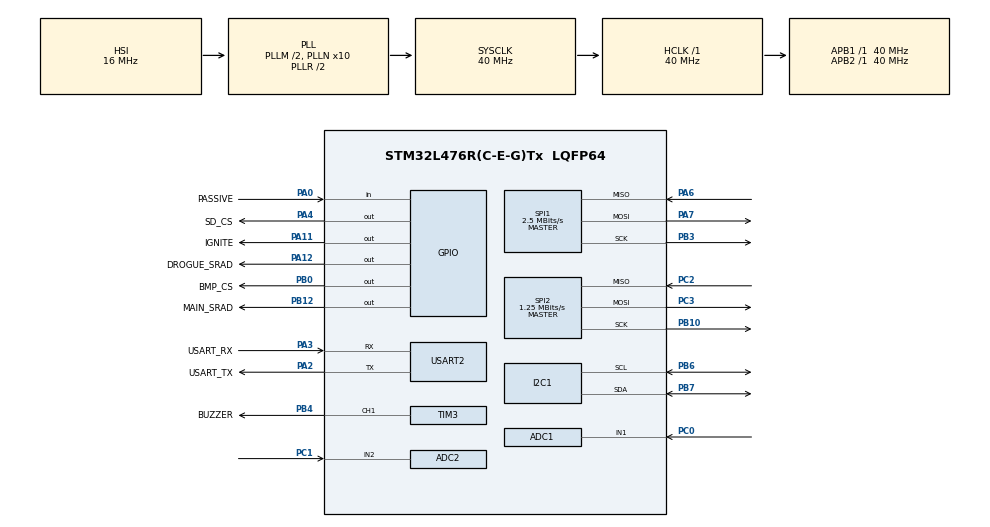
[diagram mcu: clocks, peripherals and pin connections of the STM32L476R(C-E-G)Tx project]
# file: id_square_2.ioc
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ADC1.Channel-0\#ChannelRegularConversion=ADC_CHANNEL_1
ADC1.NbrOfConversion=1
ADC1.NbrOfConversionFlag=1
ADC1.OffsetNumber-0\#ChannelRegularConversion=ADC_OFFSET_NONE
ADC1.Rank-0\#ChannelRegularConversion=1
ADC1.SamplingTime-0\#ChannelRegularConversion=ADC_SAMPLETIME_92CYCLES_5
ADC1.master=1
ADC2.Channel-4\#ChannelRegularConversion=ADC_CHANNEL_2
ADC2.NbrOfConversionFlag=1
ADC2.OffsetNumber-4\#ChannelRegularConversion=ADC_OFFSET_NONE
ADC2.Rank-4\#ChannelRegularConversion=1
ADC2.SamplingTime-4\#ChannelRegularConversion=ADC_SAMPLETIME_92CYCLES_5
FATFS._MAX_SS=4096
FATFS._USE_LFN=1
I2C1.Timing=0x00D09BE3
Mcu.Family=STM32L4
Mcu.Name=STM32L476R(C-E-G)Tx
Mcu.Package=LQFP64
NVIC.PriorityGroup=NVIC_PRIORITYGROUP_4
NVIC.TIM2_IRQn=true\:0\:0\:false\:false\:true\:true\:true\:true
PA0.GPIO_Label=PASSIVE
PA0.GPIO_PuPd=GPIO_PULLUP
PA0.Signal=GPIO_Input
PA11.GPIO_Label=IGNITE
PA11.GPIO_PuPd=GPIO_PULLDOWN
PA11.Signal=GPIO_Output
PA12.GPIO_Label=DROGUE_SRAD
PA12.GPIO_PuPd=GPIO_PULLDOWN
PA12.Signal=GPIO_Output
PA2.GPIO_Label=USART_TX
PA2.GPIO_Mode=GPIO_MODE_AF_PP
PA2.GPIO_PuPd=GPIO_NOPULL
PA2.GPIO_Speed=GPIO_SPEED_FREQ_VERY_HIGH
PA2.Mode=Asynchronous
PA2.Signal=USART2_TX
PA3.GPIO_Label=USART_RX
PA3.GPIO_Mode=GPIO_MODE_AF_PP
PA3.GPIO_PuPd=GPIO_NOPULL
PA3.GPIO_Speed=GPIO_SPEED_FREQ_VERY_HIGH
PA3.Mode=Asynchronous
PA3.Signal=USART2_RX
PA4.GPIO_Label=SD_CS
PA4.PinState=GPIO_PIN_SET
PA4.Signal=GPIO_Output
PA6.Mode=Full_Duplex_Master
PA6.Signal=SPI1_MISO
PA7.Mode=Full_Duplex_Master
PA7.Signal=SPI1_MOSI
PB0.GPIO_Label=BMP_CS
PB0.PinState=GPIO_PIN_SET
PB0.Signal=GPIO_Output
PB10.Mode=Full_Duplex_Master
PB10.Signal=SPI2_SCK
PB12.GPIO_Label=MAIN_SRAD
PB12.GPIO_PuPd=GPIO_PULLDOWN
PB12.Signal=GPIO_Output
PB3\ (JTDO-TRACESWO).Mode=Full_Duplex_Master
PB3\ (JTDO-TRACESWO).Signal=SPI1_SCK
PB4\ (NJTRST).GPIO_Label=BUZZER
PB4\ (NJTRST).Signal=S_TIM3_CH1
PB6.GPIO_Pu=GPIO_PULLUP
PB6.Mode=I2C
PB6.Signal=I2C1_SCL
PB7.GPIO_Pu=GPIO_PULLUP
PB7.Mode=I2C
PB7.Signal=I2C1_SDA
PC0.Signal=ADCx_IN1
PC1.Signal=ADCx_IN2
PC14-OSC32_IN\ (PC14).Mode=LSE-External-Oscillator
PC14-OSC32_IN\ (PC14).Signal=RCC_OSC32_IN
PC15-OSC32_OUT\ (PC15).Mode=LSE-External-Oscillator
PC15-OSC32_OUT\ (PC15).Signal=RCC_OSC32_OUT
PC2.Mode=Full_Duplex_Master
PC2.Signal=SPI2_MISO
PC3.Mode=Full_Duplex_Master
PC3.Signal=SPI2_MOSI
PH0-OSC_IN\ (PH0).Signal=RCC_OSC_IN
PH1-OSC_OUT\ (PH1).Signal=RCC_OSC_OUT
ProjectManager.HeapSize=0x200
ProjectManager.StackSize=0x400
ProjectManager.TargetToolchain=STM32CubeIDE
RCC.ADCFreq_Value=36000000
RCC.AHBFreq_Value=40000000
RCC.APB1Freq_Value=40000000
RCC.APB1TimFreq_Value=40000000
RCC.APB2Freq_Value=40000000
RCC.APB2TimFreq_Value=40000000
RCC.CortexFreq_Value=40000000
RCC.HCLKFreq_Value=40000000
RCC.HSE_VALUE=8000000
RCC.HSI_VALUE=16000000
RCC.MSI_VALUE=4000000
RCC.PLLM=2
RCC.PLLN=10
RCC.PLLSAI1N=9
RCC.PLLSAI1Q=RCC_PLLQ_DIV6
RCC.PLLSourceVirtual=RCC_PLLSOURCE_HSI
RCC.PREFETCH_ENABLE=1
RCC.SYSCLKFreq_VALUE=40000000
RCC.SYSCLKSource=RCC_SYSCLKSOURCE_PLLCLK
RCC.USBFreq_Value=12000000
RCC.VCOOutputFreq_Value=80000000
SH.ADCx_IN1.0=ADC1_IN1,IN1-Single-Ended
SH.ADCx_IN2.0=ADC2_IN2,IN2-Single-Ended
SH.S_TIM3_CH1.0=TIM3_CH1,PWM Generation1 CH1
SPI1.BaudRatePrescaler=SPI_BAUDRATEPRESCALER_16
SPI1.CalculateBaudRate=2.5 MBits/s
SPI1.DataSize=SPI_DATASIZE_8BIT
SPI1.Direction=SPI_DIRECTION_2LINES
SPI1.Mode=SPI_MODE_MASTER
SPI1.VirtualType=VM_MASTER
SPI2.BaudRatePrescaler=SPI_BAUDRATEPRESCALER_32
SPI2.CLKPhase=SPI_PHASE_2EDGE
SPI2.CLKPolarity=SPI_POLARITY_HIGH
SPI2.CalculateBaudRate=1.25 MBits/s
SPI2.DataSize=SPI_DATASIZE_8BIT
SPI2.Direction=SPI_DIRECTION_2LINES
SPI2.Mode=SPI_MODE_MASTER
SPI2.VirtualType=VM_MASTER
TIM2.Prescaler=40000-1
TIM3.Channel-PWM\ Generation1\ CH1=TIM_CHANNEL_1
TIM3.Period=1000
TIM3.Pulse-PWM\ Generation1\ CH1=500
USART2.VirtualMode-Asynchronous=VM_ASYNC
VP_FATFS_VS_Generic.Mode=User_defined
VP_TIM2_VS_ClockSourceINT.Mode=Internal
VP_TIM3_VS_ClockSourceINT.Mode=Internal
board=NUCLEO-L476RG

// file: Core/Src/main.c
/* USER CODE BEGIN Header */
/**
  ******************************************************************************
  * @file           : main.c
  * @brief          : Main program body
  ******************************************************************************
  * @attention
  *
  * Copyright (c) 2026 STMicroelectronics.
  * All rights reserved.
  *
  * This software is licensed under terms that can be found in the LICENSE file
  * in the root directory of this software component.
  * If no LICENSE file comes with this software, it is provided AS-IS.
  *
  ******************************************************************************
  */
/* USER CODE END Header */
#include "main.h"
#include "fatfs.h"

/* USER CODE BEGIN Includes */
#include "stm32_main.h"
#include <stdio.h>
/* USER CODE END Includes */

ADC_HandleTypeDef hadc1;
ADC_HandleTypeDef hadc2;

I2C_HandleTypeDef hi2c1;

SPI_HandleTypeDef hspi1;
SPI_HandleTypeDef hspi2;

TIM_HandleTypeDef htim2;
TIM_HandleTypeDef htim3;

UART_HandleTypeDef huart2;

void SystemClock_Config(void);
void PeriphCommonClock_Config(void);
static void MX_GPIO_Init(void);
static void MX_USART2_UART_Init(void);
static void MX_I2C1_Init(void);
static void MX_SPI2_Init(void);
static void MX_SPI1_Init(void);
static void MX_ADC1_Init(void);
static void MX_ADC2_Init(void);
static void MX_TIM3_Init(void);
static void MX_TIM2_Init(void);

int main(void)
{

  /* MCU Configuration--------------------------------------------------------*/

  /* Reset of all peripherals, Initializes the Flash interface and the Systick. */
  HAL_Init();

  /* Configure the system clock */
  SystemClock_Config();

  /* Configure the peripherals common clocks */
  PeriphCommonClock_Config();

  /* Initialize all configured peripherals */
  MX_GPIO_Init();
  MX_USART2_UART_Init();
  MX_I2C1_Init();
  MX_SPI2_Init();
  MX_SPI1_Init();
  MX_FATFS_Init();
  MX_ADC1_Init();
  MX_ADC2_Init();
  MX_TIM3_Init();
  MX_TIM2_Init();
  /* USER CODE BEGIN 2 */
  begin();
  /* USER CODE END 2 */

  /* Infinite loop */
  /* USER CODE BEGIN WHILE */
  while (1)
  {
	  loop();
    /* USER CODE END WHILE */

  }
}

void SystemClock_Config(void)
{
  RCC_OscInitTypeDef RCC_OscInitStruct = {0};
  RCC_ClkInitTypeDef RCC_ClkInitStruct = {0};

  /** Configure the main internal regulator output voltage
  */
  if (HAL_PWREx_ControlVoltageScaling(PWR_REGULATOR_VOLTAGE_SCALE1) != HAL_OK)
  {
    Error_Handler();
  }

  /** Initializes the RCC Oscillators according to the specified parameters
  * in the RCC_OscInitTypeDef structure.
  */
  RCC_OscInitStruct.OscillatorType = RCC_OSCILLATORTYPE_HSI;
  RCC_OscInitStruct.HSIState = RCC_HSI_ON;
  RCC_OscInitStruct.HSICalibrationValue = RCC_HSICALIBRATION_DEFAULT;
  RCC_OscInitStruct.PLL.PLLState = RCC_PLL_ON;
  RCC_OscInitStruct.PLL.PLLSource = RCC_PLLSOURCE_HSI;
  RCC_OscInitStruct.PLL.PLLM = 2;
  RCC_OscInitStruct.PLL.PLLN = 10;
  RCC_OscInitStruct.PLL.PLLP = RCC_PLLP_DIV7;
  RCC_OscInitStruct.PLL.PLLQ = RCC_PLLQ_DIV2;
  RCC_OscInitStruct.PLL.PLLR = RCC_PLLR_DIV2;
  if (HAL_RCC_OscConfig(&RCC_OscInitStruct) != HAL_OK)
  {
    Error_Handler();
  }

  /** Initializes the CPU, AHB and APB buses clocks
  */
  RCC_ClkInitStruct.ClockType = RCC_CLOCKTYPE_HCLK|RCC_CLOCKTYPE_SYSCLK
                              |RCC_CLOCKTYPE_PCLK1|RCC_CLOCKTYPE_PCLK2;
  RCC_ClkInitStruct.SYSCLKSource = RCC_SYSCLKSOURCE_PLLCLK;
  RCC_ClkInitStruct.AHBCLKDivider = RCC_SYSCLK_DIV1;
  RCC_ClkInitStruct.APB1CLKDivider = RCC_HCLK_DIV1;
  RCC_ClkInitStruct.APB2CLKDivider = RCC_HCLK_DIV1;

  if (HAL_RCC_ClockConfig(&RCC_ClkInitStruct, FLASH_LATENCY_2) != HAL_OK)
  {
    Error_Handler();
  }
}

void PeriphCommonClock_Config(void)
{
  RCC_PeriphCLKInitTypeDef PeriphClkInit = {0};

  /** Initializes the peripherals clock
  */
  PeriphClkInit.PeriphClockSelection = RCC_PERIPHCLK_ADC;
  PeriphClkInit.AdcClockSelection = RCC_ADCCLKSOURCE_PLLSAI1;
  PeriphClkInit.PLLSAI1.PLLSAI1Source = RCC_PLLSOURCE_HSI;
  PeriphClkInit.PLLSAI1.PLLSAI1M = 2;
  PeriphClkInit.PLLSAI1.PLLSAI1N = 9;
  PeriphClkInit.PLLSAI1.PLLSAI1P = RCC_PLLP_DIV7;
  PeriphClkInit.PLLSAI1.PLLSAI1Q = RCC_PLLQ_DIV6;
  PeriphClkInit.PLLSAI1.PLLSAI1R = RCC_PLLR_DIV2;
  PeriphClkInit.PLLSAI1.PLLSAI1ClockOut = RCC_PLLSAI1_ADC1CLK;
  if (HAL_RCCEx_PeriphCLKConfig(&PeriphClkInit) != HAL_OK)
  {
    Error_Handler();
  }
}

static void MX_ADC1_Init(void)
{

  ADC_MultiModeTypeDef multimode = {0};
  ADC_ChannelConfTypeDef sConfig = {0};

  /** Common config
  */
  hadc1.Instance = ADC1;
  hadc1.Init.ClockPrescaler = ADC_CLOCK_ASYNC_DIV1;
  hadc1.Init.Resolution = ADC_RESOLUTION_12B;
  hadc1.Init.DataAlign = ADC_DATAALIGN_RIGHT;
  hadc1.Init.ScanConvMode = ADC_SCAN_DISABLE;
  hadc1.Init.EOCSelection = ADC_EOC_SINGLE_CONV;
  hadc1.Init.LowPowerAutoWait = DISABLE;
  hadc1.Init.ContinuousConvMode = DISABLE;
  hadc1.Init.NbrOfConversion = 1;
  hadc1.Init.DiscontinuousConvMode = DISABLE;
  hadc1.Init.ExternalTrigConv = ADC_SOFTWARE_START;
  hadc1.Init.ExternalTrigConvEdge = ADC_EXTERNALTRIGCONVEDGE_NONE;
  hadc1.Init.DMAContinuousRequests = DISABLE;
  hadc1.Init.Overrun = ADC_OVR_DATA_PRESERVED;
  hadc1.Init.OversamplingMode = DISABLE;
  if (HAL_ADC_Init(&hadc1) != HAL_OK)
  {
    Error_Handler();
  }

  /** Configure the ADC multi-mode
  */
  multimode.Mode = ADC_MODE_INDEPENDENT;
  if (HAL_ADCEx_MultiModeConfigChannel(&hadc1, &multimode) != HAL_OK)
  {
    Error_Handler();
  }

  /** Configure Regular Channel
  */
  sConfig.Channel = ADC_CHANNEL_1;
  sConfig.Rank = ADC_REGULAR_RANK_1;
  sConfig.SamplingTime = ADC_SAMPLETIME_92CYCLES_5;
  sConfig.SingleDiff = ADC_SINGLE_ENDED;
  sConfig.OffsetNumber = ADC_OFFSET_NONE;
  sConfig.Offset = 0;
  if (HAL_ADC_ConfigChannel(&hadc1, &sConfig) != HAL_OK)
  {
    Error_Handler();
  }

}

static void MX_ADC2_Init(void)
{

  ADC_ChannelConfTypeDef sConfig = {0};

  /** Common config
  */
  hadc2.Instance = ADC2;
  hadc2.Init.ClockPrescaler = ADC_CLOCK_ASYNC_DIV1;
  hadc2.Init.Resolution = ADC_RESOLUTION_12B;
  hadc2.Init.DataAlign = ADC_DATAALIGN_RIGHT;
  hadc2.Init.ScanConvMode = ADC_SCAN_DISABLE;
  hadc2.Init.EOCSelection = ADC_EOC_SINGLE_CONV;
  hadc2.Init.LowPowerAutoWait = DISABLE;
  hadc2.Init.ContinuousConvMode = DISABLE;
  hadc2.Init.NbrOfConversion = 1;
  hadc2.Init.DiscontinuousConvMode = DISABLE;
  hadc2.Init.ExternalTrigConv = ADC_SOFTWARE_START;
  hadc2.Init.ExternalTrigConvEdge = ADC_EXTERNALTRIGCONVEDGE_NONE;
  hadc2.Init.DMAContinuousRequests = DISABLE;
  hadc2.Init.Overrun = ADC_OVR_DATA_PRESERVED;
  hadc2.Init.OversamplingMode = DISABLE;
  if (HAL_ADC_Init(&hadc2) != HAL_OK)
  {
    Error_Handler();
  }

  /** Configure Regular Channel
  */
  sConfig.Channel = ADC_CHANNEL_2;
  sConfig.Rank = ADC_REGULAR_RANK_1;
  sConfig.SamplingTime = ADC_SAMPLETIME_92CYCLES_5;
  sConfig.SingleDiff = ADC_SINGLE_ENDED;
  sConfig.OffsetNumber = ADC_OFFSET_NONE;
  sConfig.Offset = 0;
  if (HAL_ADC_ConfigChannel(&hadc2, &sConfig) != HAL_OK)
  {
    Error_Handler();
  }

}

static void MX_I2C1_Init(void)
{

  hi2c1.Instance = I2C1;
  hi2c1.Init.Timing = 0x00D09BE3;
  hi2c1.Init.OwnAddress1 = 0;
  hi2c1.Init.AddressingMode = I2C_ADDRESSINGMODE_7BIT;
  hi2c1.Init.DualAddressMode = I2C_DUALADDRESS_DISABLE;
  hi2c1.Init.OwnAddress2 = 0;
  hi2c1.Init.OwnAddress2Masks = I2C_OA2_NOMASK;
  hi2c1.Init.GeneralCallMode = I2C_GENERALCALL_DISABLE;
  hi2c1.Init.NoStretchMode = I2C_NOSTRETCH_DISABLE;
  if (HAL_I2C_Init(&hi2c1) != HAL_OK)
  {
    Error_Handler();
  }

  /** Configure Analogue filter
  */
  if (HAL_I2CEx_ConfigAnalogFilter(&hi2c1, I2C_ANALOGFILTER_ENABLE) != HAL_OK)
  {
    Error_Handler();
  }

  /** Configure Digital filter
  */
  if (HAL_I2CEx_ConfigDigitalFilter(&hi2c1, 0) != HAL_OK)
  {
    Error_Handler();
  }

}

static void MX_SPI1_Init(void)
{

  /* SPI1 parameter configuration*/
  hspi1.Instance = SPI1;
  hspi1.Init.Mode = SPI_MODE_MASTER;
  hspi1.Init.Direction = SPI_DIRECTION_2LINES;
  hspi1.Init.DataSize = SPI_DATASIZE_8BIT;
  hspi1.Init.CLKPolarity = SPI_POLARITY_LOW;
  hspi1.Init.CLKPhase = SPI_PHASE_1EDGE;
  hspi1.Init.NSS = SPI_NSS_SOFT;
  hspi1.Init.BaudRatePrescaler = SPI_BAUDRATEPRESCALER_16;
  hspi1.Init.FirstBit = SPI_FIRSTBIT_MSB;
  hspi1.Init.TIMode = SPI_TIMODE_DISABLE;
  hspi1.Init.CRCCalculation = SPI_CRCCALCULATION_DISABLE;
  hspi1.Init.CRCPolynomial = 7;
  hspi1.Init.CRCLength = SPI_CRC_LENGTH_DATASIZE;
  hspi1.Init.NSSPMode = SPI_NSS_PULSE_ENABLE;
  if (HAL_SPI_Init(&hspi1) != HAL_OK)
  {
    Error_Handler();
  }

}

static void MX_SPI2_Init(void)
{

  /* SPI2 parameter configuration*/
  hspi2.Instance = SPI2;
  hspi2.Init.Mode = SPI_MODE_MASTER;
  hspi2.Init.Direction = SPI_DIRECTION_2LINES;
  hspi2.Init.DataSize = SPI_DATASIZE_8BIT;
  hspi2.Init.CLKPolarity = SPI_POLARITY_HIGH;
  hspi2.Init.CLKPhase = SPI_PHASE_2EDGE;
  hspi2.Init.NSS = SPI_NSS_SOFT;
  hspi2.Init.BaudRatePrescaler = SPI_BAUDRATEPRESCALER_32;
  hspi2.Init.FirstBit = SPI_FIRSTBIT_MSB;
  hspi2.Init.TIMode = SPI_TIMODE_DISABLE;
  hspi2.Init.CRCCalculation = SPI_CRCCALCULATION_DISABLE;
  hspi2.Init.CRCPolynomial = 7;
  hspi2.Init.CRCLength = SPI_CRC_LENGTH_DATASIZE;
  hspi2.Init.NSSPMode = SPI_NSS_PULSE_DISABLE;
  if (HAL_SPI_Init(&hspi2) != HAL_OK)
  {
    Error_Handler();
  }

}

static void MX_TIM2_Init(void)
{

  TIM_ClockConfigTypeDef sClockSourceConfig = {0};
  TIM_MasterConfigTypeDef sMasterConfig = {0};

  htim2.Instance = TIM2;
  htim2.Init.Prescaler = 40000-1;
  htim2.Init.CounterMode = TIM_COUNTERMODE_UP;
  htim2.Init.Period = 4294967295;
  htim2.Init.ClockDivision = TIM_CLOCKDIVISION_DIV1;
  htim2.Init.AutoReloadPreload = TIM_AUTORELOAD_PRELOAD_DISABLE;
  if (HAL_TIM_Base_Init(&htim2) != HAL_OK)
  {
    Error_Handler();
  }
  sClockSourceConfig.ClockSource = TIM_CLOCKSOURCE_INTERNAL;
  if (HAL_TIM_ConfigClockSource(&htim2, &sClockSourceConfig) != HAL_OK)
  {
    Error_Handler();
  }
  sMasterConfig.MasterOutputTrigger = TIM_TRGO_RESET;
  sMasterConfig.MasterSlaveMode = TIM_MASTERSLAVEMODE_DISABLE;
  if (HAL_TIMEx_MasterConfigSynchronization(&htim2, &sMasterConfig) != HAL_OK)
  {
    Error_Handler();
  }

}

static void MX_TIM3_Init(void)
{

  TIM_ClockConfigTypeDef sClockSourceConfig = {0};
  TIM_MasterConfigTypeDef sMasterConfig = {0};
  TIM_OC_InitTypeDef sConfigOC = {0};

  htim3.Instance = TIM3;
  htim3.Init.Prescaler = 0;
  htim3.Init.CounterMode = TIM_COUNTERMODE_UP;
  htim3.Init.Period = 1000;
  htim3.Init.ClockDivision = TIM_CLOCKDIVISION_DIV1;
  htim3.Init.AutoReloadPreload = TIM_AUTORELOAD_PRELOAD_DISABLE;
  if (HAL_TIM_Base_Init(&htim3) != HAL_OK)
  {
    Error_Handler();
  }
  sClockSourceConfig.ClockSource = TIM_CLOCKSOURCE_INTERNAL;
  if (HAL_TIM_ConfigClockSource(&htim3, &sClockSourceConfig) != HAL_OK)
  {
    Error_Handler();
  }
  if (HAL_TIM_PWM_Init(&htim3) != HAL_OK)
  {
    Error_Handler();
  }
  sMasterConfig.MasterOutputTrigger = TIM_TRGO_RESET;
  sMasterConfig.MasterSlaveMode = TIM_MASTERSLAVEMODE_DISABLE;
  if (HAL_TIMEx_MasterConfigSynchronization(&htim3, &sMasterConfig) != HAL_OK)
  {
    Error_Handler();
  }
  sConfigOC.OCMode = TIM_OCMODE_PWM1;
  sConfigOC.Pulse = 500;
  sConfigOC.OCPolarity = TIM_OCPOLARITY_HIGH;
  sConfigOC.OCFastMode = TIM_OCFAST_DISABLE;
  if (HAL_TIM_PWM_ConfigChannel(&htim3, &sConfigOC, TIM_CHANNEL_1) != HAL_OK)
  {
    Error_Handler();
  }
  HAL_TIM_MspPostInit(&htim3);

}

static void MX_USART2_UART_Init(void)
{

  huart2.Instance = USART2;
  huart2.Init.BaudRate = 115200;
  huart2.Init.WordLength = UART_WORDLENGTH_8B;
  huart2.Init.StopBits = UART_STOPBITS_1;
  huart2.Init.Parity = UART_PARITY_NONE;
  huart2.Init.Mode = UART_MODE_TX_RX;
  huart2.Init.HwFlowCtl = UART_HWCONTROL_NONE;
  huart2.Init.OverSampling = UART_OVERSAMPLING_16;
  huart2.Init.OneBitSampling = UART_ONE_BIT_SAMPLE_DISABLE;
  huart2.AdvancedInit.AdvFeatureInit = UART_ADVFEATURE_NO_INIT;
  if (HAL_UART_Init(&huart2) != HAL_OK)
  {
    Error_Handler();
  }

}

static void MX_GPIO_Init(void)
{
  GPIO_InitTypeDef GPIO_InitStruct = {0};

  /* GPIO Ports Clock Enable */
  __HAL_RCC_GPIOC_CLK_ENABLE();
  __HAL_RCC_GPIOH_CLK_ENABLE();
  __HAL_RCC_GPIOA_CLK_ENABLE();
  __HAL_RCC_GPIOB_CLK_ENABLE();

  /*Configure GPIO pin Output Level */
  HAL_GPIO_WritePin(SD_CS_GPIO_Port, SD_CS_Pin, GPIO_PIN_SET);

  /*Configure GPIO pin Output Level */
  HAL_GPIO_WritePin(BMP_CS_GPIO_Port, BMP_CS_Pin, GPIO_PIN_SET);

  /*Configure GPIO pin Output Level */
  HAL_GPIO_WritePin(MAIN_SRAD_GPIO_Port, MAIN_SRAD_Pin, GPIO_PIN_RESET);

  /*Configure GPIO pin Output Level */
  HAL_GPIO_WritePin(GPIOA, IGNITE_Pin|DROGUE_SRAD_Pin, GPIO_PIN_RESET);

  /*Configure GPIO pin : PASSIVE_Pin */
  GPIO_InitStruct.Pin = PASSIVE_Pin;
  GPIO_InitStruct.Mode = GPIO_MODE_INPUT;
  GPIO_InitStruct.Pull = GPIO_PULLUP;
  HAL_GPIO_Init(PASSIVE_GPIO_Port, &GPIO_InitStruct);

  /*Configure GPIO pin : SD_CS_Pin */
  GPIO_InitStruct.Pin = SD_CS_Pin;
  GPIO_InitStruct.Mode = GPIO_MODE_OUTPUT_PP;
  GPIO_InitStruct.Pull = GPIO_NOPULL;
  GPIO_InitStruct.Speed = GPIO_SPEED_FREQ_LOW;
  HAL_GPIO_Init(SD_CS_GPIO_Port, &GPIO_InitStruct);

  /*Configure GPIO pin : BMP_CS_Pin */
  GPIO_InitStruct.Pin = BMP_CS_Pin;
  GPIO_InitStruct.Mode = GPIO_MODE_OUTPUT_PP;
  GPIO_InitStruct.Pull = GPIO_NOPULL;
  GPIO_InitStruct.Speed = GPIO_SPEED_FREQ_LOW;
  HAL_GPIO_Init(BMP_CS_GPIO_Port, &GPIO_InitStruct);

  /*Configure GPIO pin : MAIN_SRAD_Pin */
  GPIO_InitStruct.Pin = MAIN_SRAD_Pin;
  GPIO_InitStruct.Mode = GPIO_MODE_OUTPUT_PP;
  GPIO_InitStruct.Pull = GPIO_PULLDOWN;
  GPIO_InitStruct.Speed = GPIO_SPEED_FREQ_LOW;
  HAL_GPIO_Init(MAIN_SRAD_GPIO_Port, &GPIO_InitStruct);

  /*Configure GPIO pins : IGNITE_Pin DROGUE_SRAD_Pin */
  GPIO_InitStruct.Pin = IGNITE_Pin|DROGUE_SRAD_Pin;
  GPIO_InitStruct.Mode = GPIO_MODE_OUTPUT_PP;
  GPIO_InitStruct.Pull = GPIO_PULLDOWN;
  GPIO_InitStruct.Speed = GPIO_SPEED_FREQ_LOW;
  HAL_GPIO_Init(GPIOA, &GPIO_InitStruct);

}

void Error_Handler(void)
{
  __disable_irq();
  while (1)
  {
  }
}
